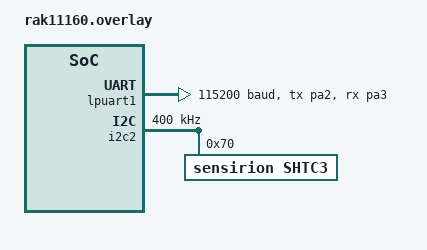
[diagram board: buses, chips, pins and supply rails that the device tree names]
/ {
	chosen {
		zephyr,console = &lpuart1;
		zephyr,shell-uart = &lpuart1;
	};
};

&lpuart1 {
	pinctrl-0 = <&lpuart1_tx_pa2 &lpuart1_rx_pa3>;
	pinctrl-names = "default";
	current-speed = <115200>;
	status = "okay";
};

&i2c2 {
	status = "okay";
	clock-frequency = <I2C_BITRATE_FAST>;
	shtc3@70 {
		compatible = "sensirion,shtc3", "sensirion,shtcx";
		reg = <0x70>;
		measure-mode = "normal";
	};
};
